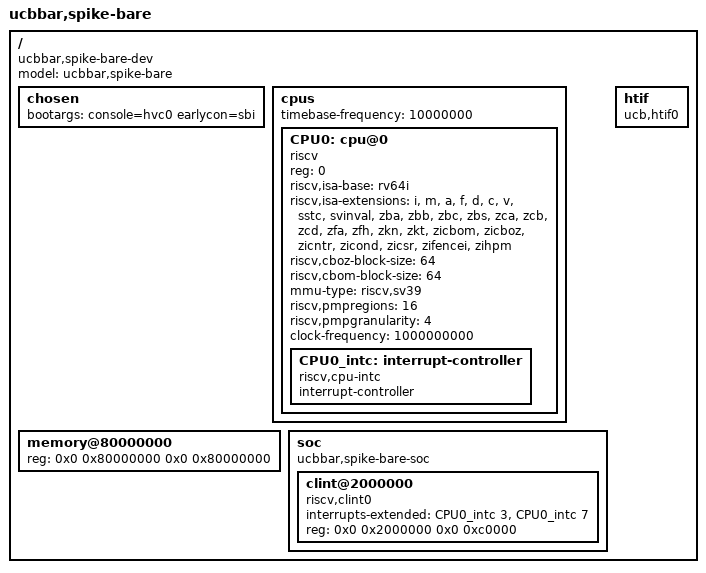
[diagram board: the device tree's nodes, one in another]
/dts-v1/;

/ {
  #address-cells = <2>;
  #size-cells = <2>;
  compatible = "ucbbar,spike-bare-dev";
  model = "ucbbar,spike-bare";
  chosen {
    bootargs = "console=hvc0 earlycon=sbi";
  };
  cpus {
    #address-cells = <1>;
    #size-cells = <0>;
    timebase-frequency = <10000000>;
    CPU0: cpu@0 {
      device_type = "cpu";
      reg = <0>;
      status = "okay";
      compatible = "riscv";
      riscv,isa-base = "rv64i";
      riscv,isa-extensions = "i", "m", "a", "f", "d", "c", "v", "sstc", "svinval", "zba", "zbb", "zbc", "zbs", "zca", "zcb", "zcd", "zfa", "zfh", "zkn", "zkt", "zicbom", "zicboz", "zicntr", "zicond", "zicsr", "zifencei", "zihpm";
      riscv,cboz-block-size = <64>;
      riscv,cbom-block-size = <64>;
      mmu-type = "riscv,sv39";
      riscv,pmpregions = <16>;
      riscv,pmpgranularity = <4>;
      clock-frequency = <1000000000>;
      CPU0_intc: interrupt-controller {
        #address-cells = <2>;
        #interrupt-cells = <1>;
        interrupt-controller;
        compatible = "riscv,cpu-intc";
      };
    };
  };
  memory@80000000 {
    device_type = "memory";
    reg = <0x0 0x80000000 0x0 0x80000000>;
  };
  soc {
    #address-cells = <2>;
    #size-cells = <2>;
    compatible = "ucbbar,spike-bare-soc", "simple-bus";
    ranges;
    clint@2000000 {
      compatible = "riscv,clint0";
      interrupts-extended = <&CPU0_intc 3 &CPU0_intc 7 >;
      reg = <0x0 0x2000000 0x0 0xc0000>;
    };
  };
  htif {
    compatible = "ucb,htif0";
  };
};
